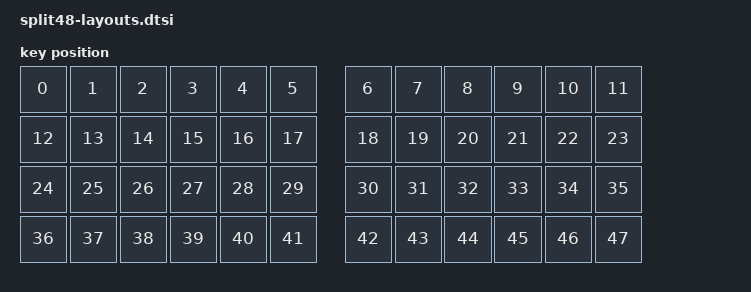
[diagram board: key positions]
#include <physical_layouts.dtsi>

/ {
    default_layout: default_layout {
        compatible = "zmk,physical-layout";
        display-name = "Default Layout";
        transform = <&default_transform>;
        kscan = <&kscan>;

        // w=幅, h=高さ, x=横位置, y=縦位置 (単位は1/1000キーサイズですが、100=1キー分として計算)
        keys
            = <
            /* Row 0 */
            &key_physical_attrs 100 100   0   0 0 0 0  &key_physical_attrs 100 100 100   0 0 0 0  &key_physical_attrs 100 100 200   0 0 0 0  &key_physical_attrs 100 100 300   0 0 0 0  &key_physical_attrs 100 100 400   0 0 0 0  &key_physical_attrs 100 100 500   0 0 0 0    &key_physical_attrs 100 100 650   0 0 0 0  &key_physical_attrs 100 100 750   0 0 0 0  &key_physical_attrs 100 100 850   0 0 0 0  &key_physical_attrs 100 100 950   0 0 0 0  &key_physical_attrs 100 100 1050   0 0 0 0  &key_physical_attrs 100 100 1150   0 0 0 0
            /* Row 1 */
            &key_physical_attrs 100 100   0 100 0 0 0  &key_physical_attrs 100 100 100 100 0 0 0  &key_physical_attrs 100 100 200 100 0 0 0  &key_physical_attrs 100 100 300 100 0 0 0  &key_physical_attrs 100 100 400 100 0 0 0  &key_physical_attrs 100 100 500 100 0 0 0    &key_physical_attrs 100 100 650 100 0 0 0  &key_physical_attrs 100 100 750 100 0 0 0  &key_physical_attrs 100 100 850 100 0 0 0  &key_physical_attrs 100 100 950 100 0 0 0  &key_physical_attrs 100 100 1050 100 0 0 0  &key_physical_attrs 100 100 1150 100 0 0 0
            /* Row 2 */
            &key_physical_attrs 100 100   0 200 0 0 0  &key_physical_attrs 100 100 100 200 0 0 0  &key_physical_attrs 100 100 200 200 0 0 0  &key_physical_attrs 100 100 300 200 0 0 0  &key_physical_attrs 100 100 400 200 0 0 0  &key_physical_attrs 100 100 500 200 0 0 0    &key_physical_attrs 100 100 650 200 0 0 0  &key_physical_attrs 100 100 750 200 0 0 0  &key_physical_attrs 100 100 850 200 0 0 0  &key_physical_attrs 100 100 950 200 0 0 0  &key_physical_attrs 100 100 1050 200 0 0 0  &key_physical_attrs 100 100 1150 200 0 0 0
            /* Row 3 */
            &key_physical_attrs 100 100   0 300 0 0 0  &key_physical_attrs 100 100 100 300 0 0 0  &key_physical_attrs 100 100 200 300 0 0 0  &key_physical_attrs 100 100 300 300 0 0 0  &key_physical_attrs 100 100 400 300 0 0 0  &key_physical_attrs 100 100 500 300 0 0 0    &key_physical_attrs 100 100 650 300 0 0 0  &key_physical_attrs 100 100 750 300 0 0 0  &key_physical_attrs 100 100 850 300 0 0 0  &key_physical_attrs 100 100 950 300 0 0 0  &key_physical_attrs 100 100 1050 300 0 0 0  &key_physical_attrs 100 100 1150 300 0 0 0
            >;
    };
};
